# f28004x_cmpss_regs register map
Vendor: Texas Instruments
Peripheral module from a debugger description file (folder C2000).
Address unit: 16 bits
Registers are 16-bit, read-write, no defined reset value unless marked. A register's access mark holds for its fields unless they carry their own. Offsets are as the file gives them; lines under a group give offsets from that group; [hi:lo] are bit positions; {n}, {i} and the like mark numbered series; 'fields as' and 'values as' point back to an identical list; <NAME> marks a mode.

## CMPSS_REGS — CMPSS Registers
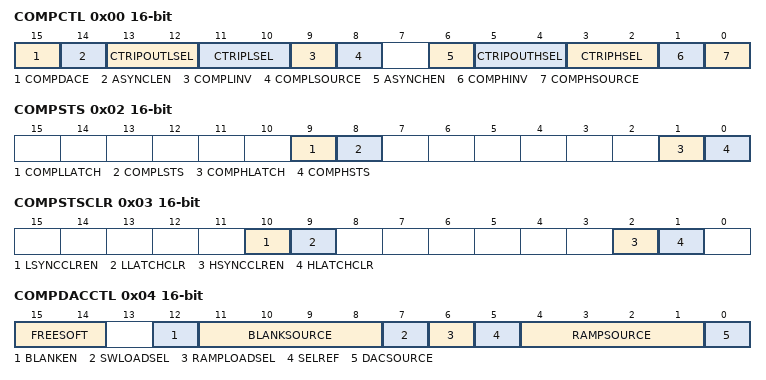
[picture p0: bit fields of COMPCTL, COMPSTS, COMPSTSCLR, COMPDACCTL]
0x00 COMPCTL — CMPSS Comparator Control Register
  [15] COMPDACE — Comparator/DAC Enable
  [14] ASYNCLEN — Low Comparator Asynchronous Path Enable
  [13:12] CTRIPOUTLSEL — Low Comparator Trip Output Select
  [11:10] CTRIPLSEL — Low Comparator Trip Select
  [9] COMPLINV — Low Comparator Invert Select
  [8] COMPLSOURCE — Low Comparator Source Select
  [6] ASYNCHEN — High Comparator Asynchronous Path Enable
  [5:4] CTRIPOUTHSEL — High Comparator Trip Output Select
  [3:2] CTRIPHSEL — High Comparator Trip Select
  [1] COMPHINV — High Comparator Invert Select
  [0] COMPHSOURCE — High Comparator Source Select
0x01 COMPHYSCTL — CMPSS Comparator Hysteresis Control Register
  [2:0] COMPHYS — Comparator Hysteresis Trim
0x02 COMPSTS ro — CMPSS Comparator Status Register
  [9] COMPLLATCH — Low Comparator Latched Status
  [8] COMPLSTS — Low Comparator Status
  [1] COMPHLATCH — High Comparator Latched Status
  [0] COMPHSTS — High Comparator Status
0x03 COMPSTSCLR access not given — CMPSS Comparator Status Clear Register
  [10] LSYNCCLREN rw — Low Comparator EPWMSYNCO Clear Enable
  [9] LLATCHCLR — Low Comparator Latched Status Clear (access R=0/W=1)
  [2] HSYNCCLREN rw — High Comparator EPWMSYNCO Clear Enable
  [1] HLATCHCLR — High Comparator Latched Status Clear (access R=0/W=1)
0x04 COMPDACCTL — CMPSS DAC Control Register
  [15:14] FREESOFT — Free/Soft Emulation Bits
  [12] BLANKEN — EPWMBLANK Enable
  [11:8] BLANKSOURCE — EPWMBLANK Source Select
  [7] SWLOADSEL — Software Load Select
  [6] RAMPLOADSEL — Ramp Load Select
  [5] SELREF — DAC Reference Select
  [4:1] RAMPSOURCE — Ramp Generator Source Control
  [0] DACSOURCE — DAC Source Control
0x06 DACHVALS — CMPSS High DAC Value Shadow Register
  [11:0] DACVAL — DAC Value Control
0x07 DACHVALA ro — CMPSS High DAC Value Active Register
  [11:0] DACVAL — DAC Value Control
0x08 RAMPMAXREFA ro — CMPSS Ramp Max Reference Active Register
  [15:0] RAMPMAXREF — Ramp Maximum Reference Active
0x0A RAMPMAXREFS — CMPSS Ramp Max Reference Shadow Register
  [15:0] RAMPMAXREF — Ramp Maximum Reference Shadow
0x0C RAMPDECVALA ro — CMPSS Ramp Decrement Value Active Register
  [15:0] RAMPDECVAL — Ramp Decrement Value Active
0x0E RAMPDECVALS — CMPSS Ramp Decrement Value Shadow Register
  [15:0] RAMPDECVAL — Ramp Decrement Value Shadow
0x10 RAMPSTS ro — CMPSS Ramp Status Register
  [15:0] RAMPVALUE
0x12 DACLVALS — CMPSS Low DAC Value Shadow Register
  [11:0] DACVAL — DAC Value Control
0x13 DACLVALA ro — CMPSS Low DAC Value Active Register
  [11:0] DACVAL — DAC Value Control
0x14 RAMPDLYA ro — CMPSS Ramp Delay Active Register
  [12:0] DELAY — Ramp Delay Value
0x15 RAMPDLYS — CMPSS Ramp Delay Shadow Register
  [12:0] DELAY — Ramp Delay Value
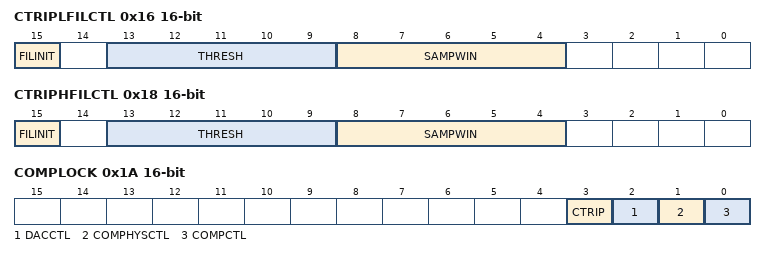
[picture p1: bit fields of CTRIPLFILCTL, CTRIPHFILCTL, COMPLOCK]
0x16 CTRIPLFILCTL access not given — CTRIPL Filter Control Register
  [15] FILINIT — Filter Initialization Bit (access R=0/W=1)
  [13:9] THRESH rw — Majority Voting Threshold
  [8:4] SAMPWIN rw — Sample Window
0x17 CTRIPLFILCLKCTL — CTRIPL Filter Clock Control Register
  [9:0] CLKPRESCALE — Sample Clock Prescale
0x18 CTRIPHFILCTL access not given — CTRIPH Filter Control Register
  fields as CTRIPLFILCTL
0x19 CTRIPHFILCLKCTL — CTRIPH Filter Clock Control Register
  [9:0] CLKPRESCALE — Sample Clock Prescale
0x1A COMPLOCK access not given — CMPSS Lock Register
  [3] CTRIP — CTRIP Lock (access R/SOnce)
  [2] DACCTL — DACCTL Lock (access R/SOnce)
  [1] COMPHYSCTL — COMPHYSCTL Lock (access R/SOnce)
  [0] COMPCTL — COMPCTL Lock (access R/SOnce)
